# CY8C5888LTI_LP097 register map
File version: 0.1
CY8C58LP
Registers are 8-bit, read-write, no defined reset value unless marked. A register's access mark holds for its fields unless they carry their own. Offsets are from the block's base; lines under a group give offsets from that group; [hi:lo] are bit positions; {n}, {i} and the like mark numbered series; 'fields as' and 'values as' point back to an identical list; <NAME> marks a mode.

## Memory map
0x00000000 I2C
0x00000000 UART_DEBUG — UART
0x00000000 UART_SRV — UART
0x00000000 UART_NL — UART

## UART_DEBUG — UART
Base 0x00000000
0x40006449 TX_UART_DEBUG_TX_DATA — TX Data Register
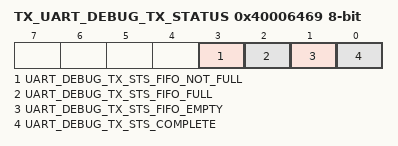
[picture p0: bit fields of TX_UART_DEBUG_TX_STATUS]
0x40006469 TX_UART_DEBUG_TX_STATUS — TX status register
  [3] UART_DEBUG_TX_STS_FIFO_NOT_FULL ro, [2] UART_DEBUG_TX_STS_FIFO_FULL ro, [1] UART_DEBUG_TX_STS_FIFO_EMPTY ro, [0] UART_DEBUG_TX_STS_COMPLETE ro

## UART_SRV — UART
Base 0x00000000
0x40006428 RX_UART_SRV_RX_ADDRESS1 — RX Address1 Register
0x40006438 RX_UART_SRV_RX_ADDRESS2 — RX Address2 Register
0x40006448 RX_UART_SRV_RX_DATA — RX Data Register
0x4000644A TX_UART_SRV_TX_DATA — TX Data Register
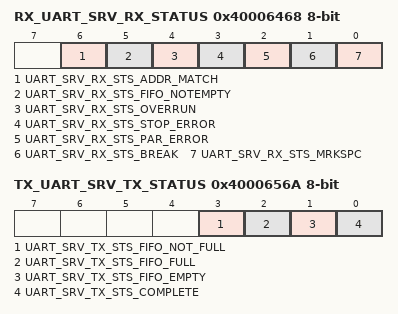
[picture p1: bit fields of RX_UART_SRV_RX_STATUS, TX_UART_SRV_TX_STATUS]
0x40006468 RX_UART_SRV_RX_STATUS — RX status register
  [6] UART_SRV_RX_STS_ADDR_MATCH ro, [5] UART_SRV_RX_STS_FIFO_NOTEMPTY ro, [4] UART_SRV_RX_STS_OVERRUN ro, [3] UART_SRV_RX_STS_STOP_ERROR ro, [2] UART_SRV_RX_STS_PAR_ERROR ro, [1] UART_SRV_RX_STS_BREAK ro, [0] UART_SRV_RX_STS_MRKSPC ro
0x4000656A TX_UART_SRV_TX_STATUS — TX status register
  [3] UART_SRV_TX_STS_FIFO_NOT_FULL ro, [2] UART_SRV_TX_STS_FIFO_FULL ro, [1] UART_SRV_TX_STS_FIFO_EMPTY ro, [0] UART_SRV_TX_STS_COMPLETE ro

## UART_NL — UART
Base 0x00000000
0x4000642C RX_UART_NL_RX_ADDRESS1 — RX Address1 Register
0x4000643C RX_UART_NL_RX_ADDRESS2 — RX Address2 Register
0x4000644C RX_UART_NL_RX_DATA — RX Data Register
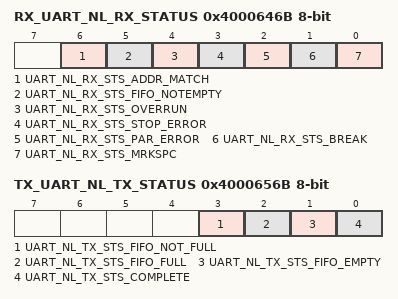
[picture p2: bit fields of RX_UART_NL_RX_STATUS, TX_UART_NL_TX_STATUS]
0x4000646B RX_UART_NL_RX_STATUS — RX status register
  [6] UART_NL_RX_STS_ADDR_MATCH ro, [5] UART_NL_RX_STS_FIFO_NOTEMPTY ro, [4] UART_NL_RX_STS_OVERRUN ro, [3] UART_NL_RX_STS_STOP_ERROR ro, [2] UART_NL_RX_STS_PAR_ERROR ro, [1] UART_NL_RX_STS_BREAK ro, [0] UART_NL_RX_STS_MRKSPC ro
0x4000654B TX_UART_NL_TX_DATA — TX Data Register
0x4000656B TX_UART_NL_TX_STATUS — TX status register
  [3] UART_NL_TX_STS_FIFO_NOT_FULL ro, [2] UART_NL_TX_STS_FIFO_FULL ro, [1] UART_NL_TX_STS_FIFO_EMPTY ro, [0] UART_NL_TX_STS_COMPLETE ro
